# G32R501 register map
Vendor: Geehy Semiconductor Co., Ltd.; Series: G32R5; File version: 1.0
CPU: CM55 r0p1, little endian, MPU, FPU, double-precision FPU, DSP, VTOR, 4 interrupt priority bits
Registers are 32-bit, read-write, reset 0x0 unless marked. A register's access mark holds for its fields unless they carry their own. Offsets are from the block's base; [hi:lo] are bit positions.

## PMBUS
Base 0x50100800
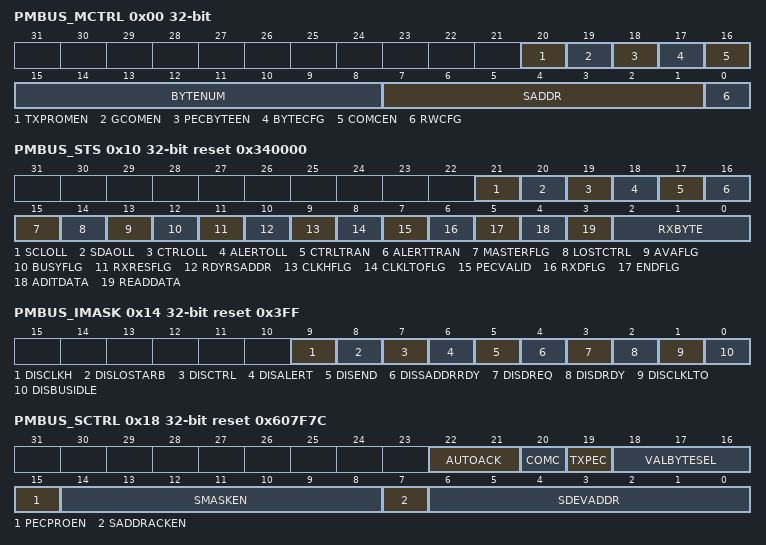
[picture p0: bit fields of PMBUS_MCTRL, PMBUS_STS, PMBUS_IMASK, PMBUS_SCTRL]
0x00 PMBUS_MCTRL — PMBUS Master Mode Control Register
  [20] TXPROMEN — Transmit Process Call message Enable
  [19] GCOMEN — Transmit of Group Command message Enable
  [18] PECBYTEEN — PEC byte Enables
  [17] BYTECFG — Use bytes for Command Code Configure
  [16] COMCEN — use of command code on Master initiated messages Enable
  [15:8] BYTENUM — number of bytes of data transferred in the current message
  [7:1] SADDR — current message slave address
  [0] RWCFG — message read and write Configure
0x04 PMBUS_TXB — PMBUS Transmit Buffer
  [31:0] TXB — Transmit Buffer
0x08 PMBUS_RXB ro — PMBUS Receive buffer
  [31:0] RXB — Receive Buffer
0x0C PMBUS_ACK — PMBUS Acknowledge Register
  [0] ACK — Acknowledge received data
0x10 PMBUS_STS ro reset 0x340000 — PMBUS Status Register
  [21] SCLOLL — Clock pin at logic level high
  [20] SDAOLL — Data pin at logic level high
  [19] CTRLOLL — Control pin at logic level high
  [18] ALERTOLL — Alert pin at logic level high
  [17] CTRLTRAN — Control pin transitioned
  [16] ALERTTRAN — Alert pin transitioned
  [15] MASTERFLG — Master Mode FLag
  [14] LOSTCTRL — Master lost control of PMBus
  [13] AVAFLG — Available Flag
  [12] BUSYFLG — Busy Flag
  [11] RXRESFLG — Received Repeated Star Flag
  [10] RDYRSADDR — Ready read slave address
  [9] CLKHFLG — Clock High Flag
  [8] CLKLTOFLG — Clock low timeout Flag
  [7] PECVALID — Received PEC is valid
  [6] RXDFLG — Receive data Flag
  [5] ENDFLG — Current message End Flag
  [4] ADITDATA — Request additional data
  [3] READDATA — Read data prior to bus activity
  [2:0] RXBYTE — Receive byte Selcet
0x14 PMBUS_IMASK reset 0x3FF — PMBUS Interrupt Mask Register
  [9] DISCLKH — Disables Clock High generation interrupt
  [8] DISLOSTARB — Disables Lost Arbitration generation interrupt
  [7] DISCTRL — Disables Control generation interrupt
  [6] DISALERT — Disables Alert generation interrupt
  [5] DISEND — Disables Message End generation interrupt
  [4] DISSADDRRDY — Disables Slave Address Ready generation interrupt
  [3] DISDREQ — Disables Data Request generation interrupt
  [2] DISDRDY — Disables Data Ready generation interrupt
  [1] DISCLKLTO — Disables Clock Low Timeout generation interrupt
  [0] DISBUSIDLE — Disables Bus Idle generation interrupt
0x18 PMBUS_SCTRL reset 0x607F7C — PMBUS Slave Mode Configuration Register
  [22:21] AUTOACK — Slave mode automatic acknowledge data bytes Configure
  [20] COMC — Data Request flag generated after receive of command code
  [19] TXPEC — Transmit a PEC byte at the end of the message
  [18:16] VALBYTESEL — Valid bytes Select
  [15] PECPROEN — PEC processing enable
  [14:8] SMASKEN — Slave mask enable
  [7] SADDRACKEN — Manual Slave Address Acknowledgement Enable
  [6:0] SDEVADDR — Slave current device address Set
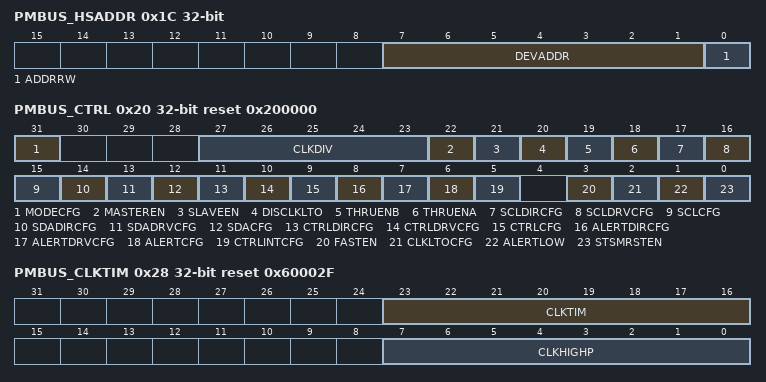
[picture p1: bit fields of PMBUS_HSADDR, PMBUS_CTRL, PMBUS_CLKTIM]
0x1C PMBUS_HSADDR ro — PMBUS Hold Slave Address Register
  [7:1] DEVADDR — Stored device address
  [0] ADDRRW — Address stored R/W bit
0x20 PMBUS_CTRL reset 0x200000 — PMBUS Control Register
  [31] MODECFG — Mode Configure
  [27:23] CLKDIV — SYSCLK clock divider
  [22] MASTEREN — PMBus Master Enables
  [21] SLAVEEN — PMBus Slave Enables
  [20] DISCLKLTO — Clock Low Timeout Disabled
  [19] THRUENB — Current source for PMBus address detection thru ADC enable
  [18] THRUENA — Current source for PMBus address detection thru ADC enable
  [17] SCLDIRCFG — Clock pin direction configure
  [16] SCLDRVCFG — GPIO Mode Clock pin driven configure
  [15] SCLCFG — Clock pin configure
  [14] SDADIRCFG — Data pin direction configure
  [13] SDADRVCFG — GPIO Mode Data pin driven configure
  [12] SDACFG — Data pin configure
  [11] CTRLDIRCFG — Control pin direction configure
  [10] CTRLDRVCFG — GPIO Mode Control pin driven configure
  [9] CTRLCFG — Control pin configure
  [8] ALERTDIRCFG — Alert pin direction configure
  [7] ALERTDRVCFG — GPIO Mode Alert pin driven configure
  [6] ALERTCFG — Alert pin configure
  [5] CTRLINTCFG — Control generated interrupt configure
  [3] FASTEN — Fast Mode enable
  [2] CLKLTOCFG — Clock low timeout generated interrupt configure
  [1] ALERTLOW — PMBus Alert driven low by slave
  [0] STSMRSTEN — State machines reset enable
0x24 PMBUS_TIMCTRL — PMBUS Timing Control Register
  [0] PARCFG — FSM parameters Configure
0x28 PMBUS_CLKTIM reset 0x60002F — PMBUS Clock Timing Register
  [23:16] CLKTIM — number of FSM input clock in the PMBUS master clock period
  [7:0] CLKHIGHP — number of FSM input clock in the PMBUS master clock high pulse Set
0x2C PMBUS_STATIM reset 0x2F — PMBUS Start Setup Time Register
  [7:0] STATIM — The time between the last rising edge of the PMBus master clock and the next starting edge
0x30 PMBUS_BUSIDTIM reset 0x1F3 — PMBUS Bus Idle Time Register
  [9:0] BUSIDTIM — Bus Idle Time Set
0x34 PMBUS_CLKLTOTIIM reset 0x5572F — PMBUS Clock Low Timeout Value Register
  [19:0] CLKLTOTIIM — Clock Low Timeout Time
0x38 PMBUS_CLKHTOTIIM reset 0x1F3 — PMBUS Clock High Timeout Value Register
  [9:0] CLKHTOTIIM — Clock High Timeout Time
